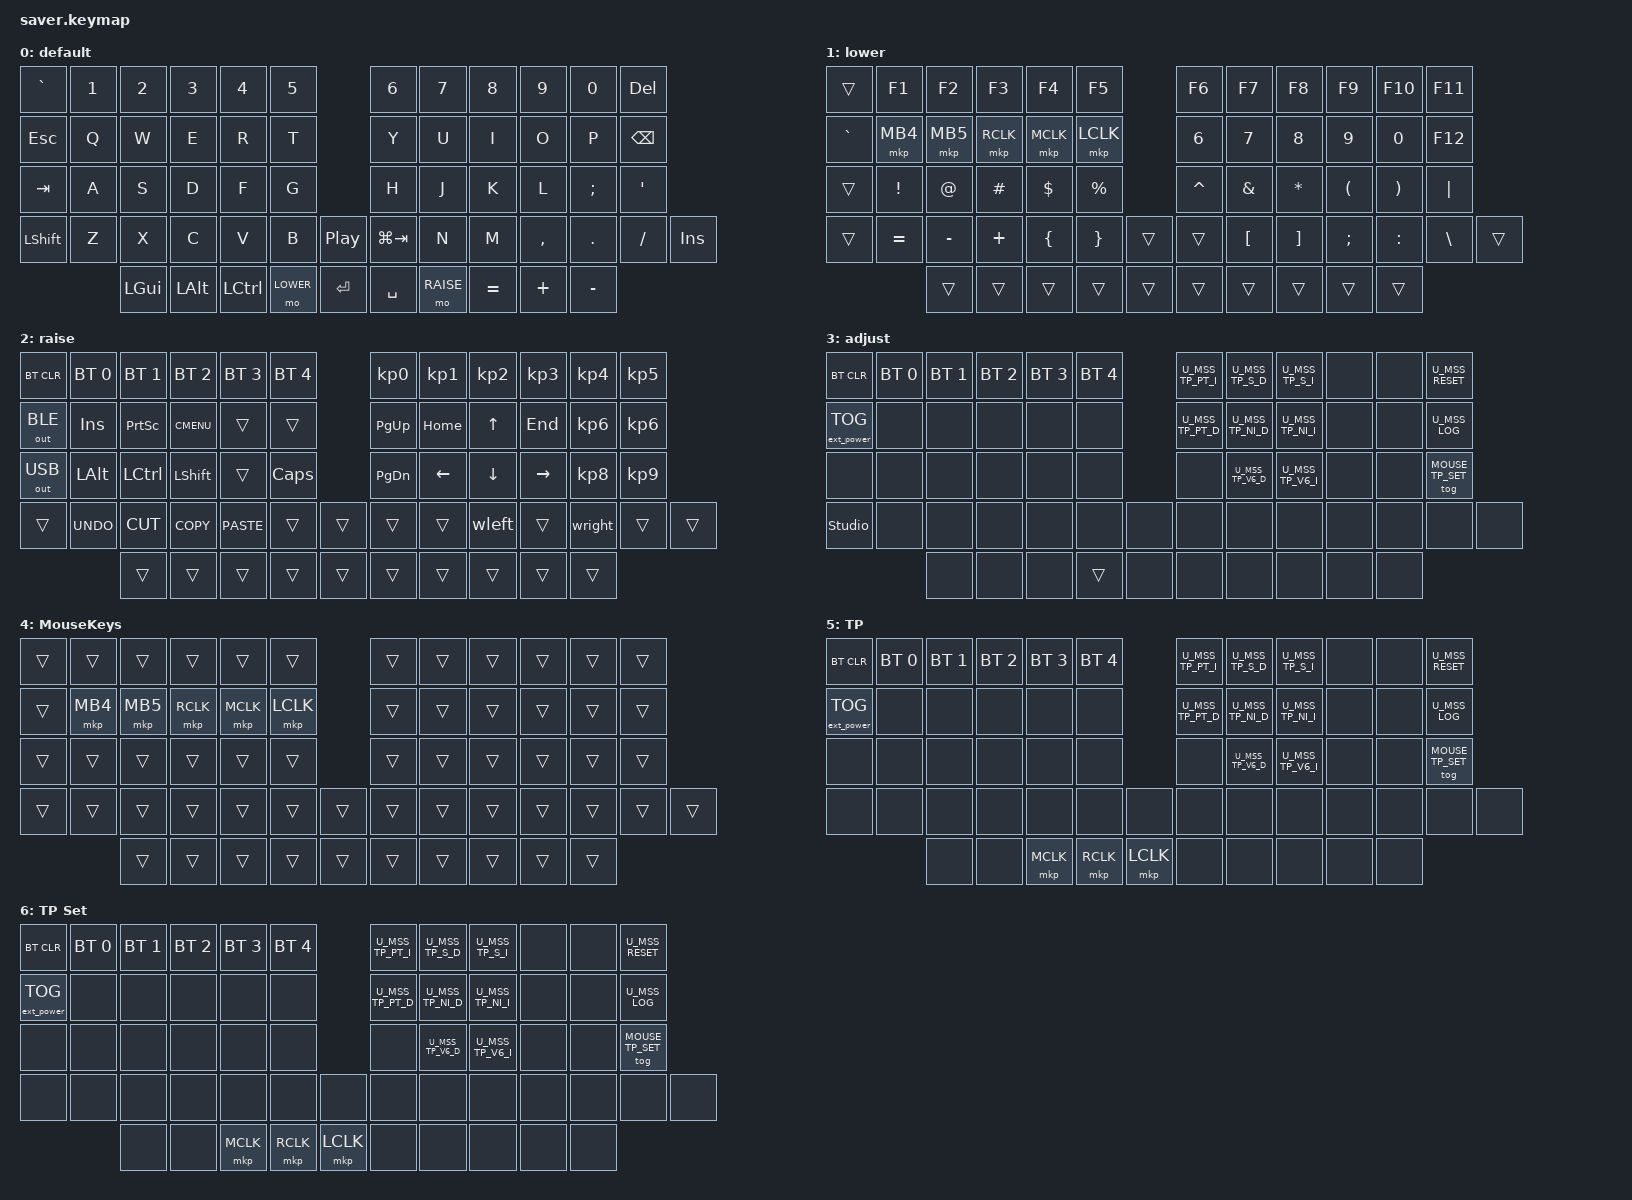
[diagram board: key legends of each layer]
/*
 * Copyright (c) 2020 The ZMK Contributors
 *
 * SPDX-License-Identifier: MIT
 */

#include <behaviors.dtsi>
#include <dt-bindings/zmk/keys.h>
#include <dt-bindings/zmk/bt.h>
#include <dt-bindings/zmk/ext_power.h>
#include <dt-bindings/zmk/outputs.h>

#define BASE 0
#define LOWER 1
#define RAISE 2
#define ADJUST 3


#define MOUSE_KEYS 4
#define MOUSE_TP 5
#define MOUSE_TP_SET 6

/*
 * Defines to enable/disable features
 *
 * These defines allow us to conditionally enable and disable parts of the keymap config.
 *
 * For example, if we decide to build the firmware without the mouse features, we can
 * disable all the config options that rely on those forks and modules without having
 * to edit the entire keymap file manually every time.
 */

#define HAS_MOUSE_KEYS
#define HAS_MOUSE_TP

#ifdef HAS_MOUSE_KEYS
  #include <dt-bindings/zmk/mouse.h>
  #include <behaviors/mouse_keys.dtsi>
#endif  // HAS_MOUSE_KEYS

#ifdef HAS_MOUSE_TP
  // We store the trackpoint settings in a separate file
  // to make organization a little easier.
  #include "include/mouse_tp.dtsi"
#endif  // HAS_MOUSE_TP



// Adjust layer keys based on enabled features.
//
// This prevents build errors when we build the firmware
// without the mouse keys PR or the TP module.
#ifdef HAS_MOUSE_KEYS
  #define U_THUMB_INNER &mo MOUSE_KEYS
#else
  #define U_THUMB_INNER &none
#endif  // HAS_MOUSE_KEYS

#ifdef HAS_MOUSE_TP
  #define U_TOG_TP_SET &tog MOUSE_TP_SET
#else
  #define U_TOG_TP_SET &none
#endif  // HAS_MOUSE_TP



/ {
 macros {
        wleft: wleft {
            compatible = "zmk,behavior-macro";
            #binding-cells = <0>;
            bindings
                = <&macro_press &kp LGUI>, <&macro_press &kp LCTRL>
                , <&macro_tap &kp LEFT>
                , <&macro_release &kp LGUI>,<&macro_release &kp LCTRL>
                ;
        };
        wright: wright {
            compatible = "zmk,behavior-macro";
            #binding-cells = <0>;
            bindings
                = <&macro_press &kp LGUI>, <&macro_press &kp LCTRL>
                , <&macro_tap &kp RIGHT>
                , <&macro_release &kp LGUI>,<&macro_release &kp LCTRL>
                ;
        };
    };

    behaviors {
        rot_kp: sensor_rotate_kp {
            compatible = "zmk,behavior-sensor-rotate";
            #sensor-binding-cells = <0>;
            bindings = <&wleft>, <&wright>;
        };
    };

   // Activate ADJUST layer by pressing raise and lower
    conditional_layers {
        compatible = "zmk,conditional-layers";
        adjust_layer {
            if-layers = <LOWER RAISE>;
            then-layer = <ADJUST>;
        };
    };

    keymap {
        compatible = "zmk,keymap";

        default_layer {
            display-name = "default";
// ------------------------------------------------------------------------------------------------------------
// |   `   |  1  |  2  |  3   |  4   |  5   |                   |  6   |  7    |  8    |  9   |   0   |  DEL  |
// |  ESC  |  Q  |  W  |  E   |  R   |  T   |                   |  Y   |  U    |  I    |  O   |   P   | BKSPC |
// |  TAB  |  A|afi  |  S  |  D   |  F   |  G   |                   |  H   |  J    |  K    |  L   |   ;   INS   '   |
// | SHIFT |  Z  |  X  |  C   |  V   |  B   |  PAUSE  |  |       |  N   |  M    |  ,    |  .   |   /   | SHIFT |
//               | GUI | ALT  | CTRL | LOWER|  ENTER |  | SPACE | RAISE| =  | +   | -  |
            bindings = <
&kp GRAVE &kp N1 &kp N2   &kp N3   &kp N4    &kp N5                           &kp N6 &kp N7    &kp N8    &kp N9   &kp N0   &kp DELETE
&kp ESC   &kp Q  &kp W    &kp E    &kp R     &kp T                            &kp Y  &kp U     &kp I     &kp O    &kp P    &kp BSPC
&kp TAB   &kp A  &kp S    &kp D    &kp F     &kp G                            &kp H  &kp J     &kp K     &kp L    &kp SEMI &kp SQT
&kp LSHFT &kp Z  &kp X    &kp C    &kp V     &kp B      &kp C_PLAY_PAUSE  &kp LG(TAB)      &kp N  &kp M     &kp COMMA &kp DOT  &kp FSLH &kp INS
                 &kp LGUI &kp LALT &kp LCTRL &mo LOWER  &kp RET    &kp SPACE  &mo RAISE  &kp EQUAL &kp PLUS  &kp MINUS
            >;

            sensor-bindings = <&inc_dec_kp C_VOL_DN C_VOL_UP &rot_kp>;
        };

        lower_layer {
            display-name = "lower";
// TODO: Some binds are waiting for shifted keycode support.
// ------------------------------------------------------------------------------------------------------------
// |       |  F1 |  F2 |  F3  |  F4  |  F5  |                   |  F6  |  F7   |  F8   |  F9  |  F10  |  F11  |
// |   `   |  1  |  2  |  3   |  4   |  5   |                   |  6   |  7    |  8    |  9   |   0   |  F12  |
// |       |  !  |  @  |  #   |  $   |  %   |                   |  ^   |  &    |  *    |  (   |   )   |   |   |
// |       |  =  |  -  |  +   |  {   |  }   |        |  |       |  [   |  ]    |  ;    |  :   |   \   |       |
//               |     |      |      |      |        |  |       |      |       |       |      |
            bindings = <
&trans    &kp F1    &kp F2    &kp F3      &kp F4    &kp F5                    &kp F6    &kp F7   &kp F8    &kp F9    &kp F10   &kp F11
&kp GRAVE &mkp MB4  &mkp MB5  &mkp RCLK   &mkp MCLK &mkp LCLK                    &kp N6    &kp N7   &kp N8    &kp N9    &kp N0    &kp F12
&trans    &kp EXCL  &kp AT    &kp HASH    &kp DLLR  &kp PRCNT                 &kp CARET &kp AMPS &kp ASTRK &kp LPAR  &kp RPAR  &kp PIPE
&trans    &kp EQUAL &kp MINUS &kp PLUS &kp LBRC  &kp RBRC   &trans &trans  &kp LBKT  &kp RBKT &kp SEMI  &kp COLON &kp BSLH  &trans
                    &trans    &trans      &trans    &trans     &trans &trans  &trans    &trans   &trans    &trans
            >;

            sensor-bindings = <&inc_dec_kp C_VOL_UP C_VOL_DN &inc_dec_kp PG_UP PG_DN>;
        };

        raise_layer {
            display-name = "raise";
// ------------------------------------------------------------------------------------------------------------
// | BTCLR | BT1  | BT2  |  BT3  |  BT4  |  BT5 |                | num0 | num1 | num2  | num3 | num4  | num5  |
// |OUT_BLE| INS  | PSCR | GUI   |       |      |                | PGUP | HOME |   ^   | END  | num6  | num7  |
// |OUT_USB| ALT  | CTRL | SHIFT |       | CAPS |                | PGDN |   <- |   v   |  ->  | num8  | num9  |
// |       | UNDO | CUT  | COPY  | PASTE |      |      |  |      |      |wleft |       |wright|       |       |
//                |      |       |       |      |      |  |      |      |      |       |      |
            bindings = <
&bt BT_CLR      &bt BT_SEL 0 &bt BT_SEL 1 &bt BT_SEL 2 &bt BT_SEL 3 &bt BT_SEL 4                  &kp KP_N0 &kp KP_N1 &kp KP_N2 &kp KP_N3  &kp KP_N4 &kp KP_N5
&out OUT_BLE    &kp INS      &kp PSCRN    &kp K_CMENU  &trans       &trans                        &kp PG_UP &kp HOME  &kp UP    &kp END    &kp KP_N6 &kp KP_N6
&out OUT_USB    &kp LALT     &kp LCTRL    &kp LSHFT    &trans       &kp CLCK                      &kp PG_DN &kp LEFT  &kp DOWN  &kp RIGHT  &kp KP_N8 &kp KP_N9
&trans          &kp K_UNDO   &kp K_CUT    &kp K_COPY   &kp K_PASTE  &trans        &trans  &trans  &trans    &wleft    &trans    &wright    &trans    &trans
                        &trans       &trans       &trans       &trans        &trans  &trans  &trans    &trans    &trans   &trans
            >;
            sensor-bindings = <&inc_dec_kp C_VOL_UP C_VOL_DN &inc_dec_kp PG_UP PG_DN>;
        };

        adjust_layer {
// ----------------------------------------------------------------------------------------------------------------------------
// | BTCLR  |  BT1    |  BT2    |   BT3   |   BT4   |   BT5   |                  | PTS+ | SENS- | SENS+ |      |       |CONFRST |
// | EXTPWR | RGB_HUD | RGB_HUI | RGB_SAD | RGB_SAI | RGB_EFF |                  | PTS- | INERT-|INERT+ |      |       |CONFLOG |
// |        | RGB_BRD | RGB_BRI |         |         |         |                  |      | VAL6- | VAL6+ |      |       |TPSET   |
// | studio |         |         |         |         |         | RGB_TOG | |      |      |      |       |      |       |       |
//                    |         |         |         |         |         | |      |      |      |       |      |
            display-name = "adjust";
            bindings = <
&bt BT_CLR        &bt BT_SEL 0    &bt BT_SEL 1    &bt BT_SEL 2    &bt BT_SEL 3    &bt BT_SEL 4                            U_MSS_TP_PT_I  U_MSS_TP_S_D   U_MSS_TP_S_I &none &none U_MSS_RESET
&ext_power EP_TOG &none &none &none &none &none                         U_MSS_TP_PT_D  U_MSS_TP_NI_D  U_MSS_TP_NI_I &none &none U_MSS_LOG
&none             &none &none &none           &none           &none                                   &none          U_MSS_TP_V6_D  U_MSS_TP_V6_I &none &none U_TOG_TP_SET
&studio_unlock    &none           &none           &none           &none           &none            &none &none  &none &none &none &none &none &none
                                  &none           &none           &none           &trans           &none           &none  &none &none &none &none
            >;

            // sensor-bindings = <&inc_dec_kp RGB_BRD RGB_BRI &inc_dec_kp RGB_SAD RGB_SAI>;
        };

#ifdef HAS_MOUSE_KEYS

    MouseKeys_layer {
      display-name = "MouseKeys";
            bindings = <
&trans &trans   &trans   &trans    &trans    &trans                             &trans    &trans    &trans   &trans   &trans &trans
&trans &mkp MB4 &mkp MB5 &mkp RCLK &mkp MCLK &mkp LCLK                          &trans    &trans    &trans   &trans   &trans &trans
&trans &trans   &trans   &trans    &trans    &trans                             &trans    &trans    &trans   &trans   &trans &trans
&trans &trans   &trans   &trans    &trans    &trans    &trans         &trans    &trans    &trans    &trans   &trans   &trans &trans
                &trans   &trans    &trans    &trans    &trans         &trans    &trans    &trans    &trans   &trans
            >;
    };

#endif


#ifdef HAS_MOUSE_TP

    // Automatically activated when the mouse or trackpoint moves.
    // Configured in `include/mouse_tp.dtsi`.
    MouseTP_layer {
      display-name = "TP";
      bindings = <
&bt BT_CLR        &bt BT_SEL 0    &bt BT_SEL 1    &bt BT_SEL 2    &bt BT_SEL 3    &bt BT_SEL 4                            U_MSS_TP_PT_I  U_MSS_TP_S_D   U_MSS_TP_S_I &none &none U_MSS_RESET
&ext_power EP_TOG &none &none &none &none &none                         U_MSS_TP_PT_D  U_MSS_TP_NI_D  U_MSS_TP_NI_I &none &none U_MSS_LOG
&none             &none &none &none           &none           &none                                   &none          U_MSS_TP_V6_D  U_MSS_TP_V6_I &none &none U_TOG_TP_SET
&none             &none           &none           &none           &none           &none            &none &none  &none &none &none &none &none &none
                                  &none           &none           &mkp MCLK       &mkp RCLK        &mkp LCLK           &none  &none &none &none &none
            >;
    };

    // You can find the defines for the actual key press behaviors in `include/mouse_tp.dtsi`.
    MouseSettings_layer {
      display-name = "TP Set";
      bindings = <
&bt BT_CLR        &bt BT_SEL 0    &bt BT_SEL 1    &bt BT_SEL 2    &bt BT_SEL 3    &bt BT_SEL 4                            U_MSS_TP_PT_I  U_MSS_TP_S_D   U_MSS_TP_S_I &none &none U_MSS_RESET
&ext_power EP_TOG &none &none &none &none &none                         U_MSS_TP_PT_D  U_MSS_TP_NI_D  U_MSS_TP_NI_I &none &none U_MSS_LOG
&none             &none &none &none           &none           &none                                   &none          U_MSS_TP_V6_D  U_MSS_TP_V6_I &none &none U_TOG_TP_SET
&none             &none           &none           &none           &none           &none            &none &none  &none &none &none &none &none &none
                                  &none           &none           &mkp MCLK       &mkp RCLK        &mkp LCLK           &none  &none &none &none &none
            >;
    };

#endif

    };
};
